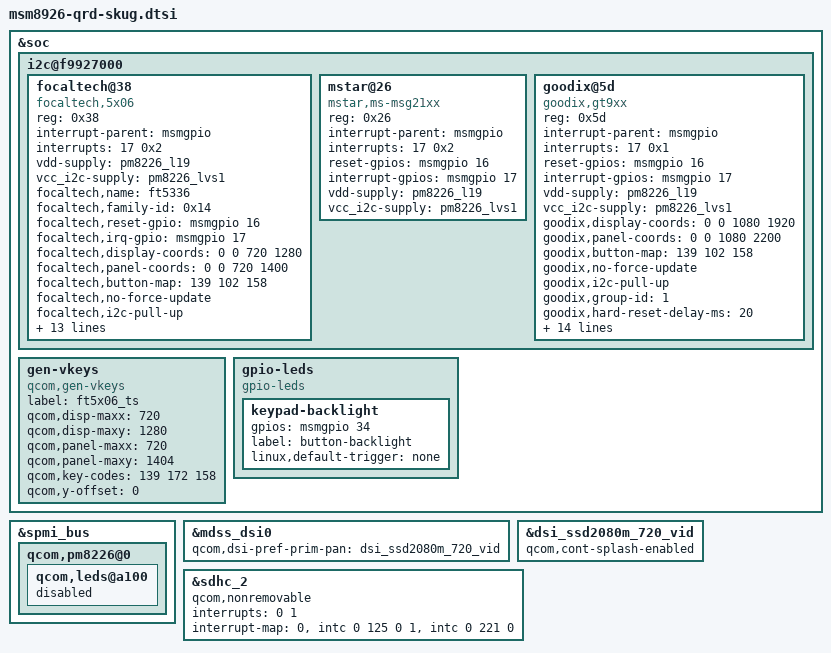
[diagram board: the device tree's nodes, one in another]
/* Copyright (c) 2013-2014, The Linux Foundation. All rights reserved.
 *
 * This program is free software; you can redistribute it and/or modify
 * it under the terms of the GNU General Public License version 2 and
 * only version 2 as published by the Free Software Foundation.
 *
 * This program is distributed in the hope that it will be useful,
 * but WITHOUT ANY WARRANTY; without even the implied warranty of
 * MERCHANTABILITY or FITNESS FOR A PARTICULAR PURPOSE.  See the
 * GNU General Public License for more details.
 */

/include/ "msm8226-qrd.dtsi"
/include/ "msm8926-camera-sensor-qrd.dtsi"

//xiangdong delete for battery identify issue begin
/*
&qrd_batterydata {
	qcom,rpull-up-kohm = <100>;
	qcom,vref-batt-therm = <1800000>;

	/include/ "batterydata-qrd-4v2-2000mah.dtsi"
};

&pm8226_bms {
	qcom,battery-data = <&qrd_batterydata>;
};

&pm8226_chg {
	qcom,battery-data = <&qrd_batterydata>;
};
*/
//xiangdong delete for battery identify issue end

&soc {
	i2c@f9927000 { /* BLSP1 QUP5 */
		focaltech@38 {
			compatible = "focaltech,5x06";
			reg = <0x38>;
			interrupt-parent = <&msmgpio>;
			interrupts = <17 0x2>;
			vdd-supply = <&pm8226_l19>;
			vcc_i2c-supply = <&pm8226_lvs1>;
			focaltech,name = "ft5336";
			focaltech,family-id = <0x14>;
			focaltech,reset-gpio = <&msmgpio 16 0x00>;
			focaltech,irq-gpio = <&msmgpio 17 0x00>;
			focaltech,display-coords = <0 0 720 1280>;
			focaltech,panel-coords = <0 0 720 1400>;
			focaltech,button-map= <139 102 158>;
			focaltech,no-force-update;
			focaltech,i2c-pull-up;
			focaltech,group-id = <1>;
			focaltech,hard-reset-delay-ms = <20>;
			focaltech,soft-reset-delay-ms = <200>;
			focaltech,num-max-touches = <5>;
			focaltech,fw-name = "ft_8926_qrd_fw.bin";
			focaltech,fw-delay-aa-ms = <30>;
			focaltech,fw-delay-55-ms = <30>;
			focaltech,fw-upgrade-id1 = <0x11>;
			focaltech,fw-upgrade-id2 = <0x11>;
			focaltech,fw-delay-readid-ms = <10>;
			focaltech,fw-delay-era-flsh-ms = <2000>;
			focaltech,fw-auto-cal;
			focaltech,ignore-id-check;
		};
		/* lichm merge for mstar tp begin */
		mstar@26 {
			compatible = "mstar,ms-msg21xx";
			reg = <0x26>;
			interrupt-parent = <&msmgpio>;
			interrupts = <17 0x2>;
			reset-gpios = <&msmgpio 16 0x00>;
			interrupt-gpios = <&msmgpio 17 0x00>;
			vdd-supply = <&pm8226_l19>;
			vcc_i2c-supply = <&pm8226_lvs1>;
		};
		/* lichm merge for mstar tp end */

		/* wuchx merge for goodix tp begin */
		goodix@5d {
			compatible = "goodix,gt9xx";
			reg = <0x5d>;
			interrupt-parent = <&msmgpio>;
			interrupts = <17 0x1>;
			reset-gpios = <&msmgpio 16 0x00>;
			interrupt-gpios = <&msmgpio 17 0x00>;
			vdd-supply = <&pm8226_l19>;
			vcc_i2c-supply = <&pm8226_lvs1>;
			/*TYDRV:liujie add for goodix TP dt begin 20140613*/
			goodix,display-coords = <0 0 1080 1920>;
			goodix,panel-coords = <0 0 1080 2200>;
			goodix,button-map= <139 102 158>;
			goodix,no-force-update;
			goodix,i2c-pull-up;
			goodix,group-id = <1>;
			goodix,hard-reset-delay-ms = <20>;
			goodix,soft-reset-delay-ms = <200>;
			goodix,num-max-touches = <5>;
			goodix,fw-name = "gtp_8926_qrd_fw.bin";
			goodix,fw-delay-aa-ms = <30>;
			goodix,fw-delay-55-ms = <30>;
			goodix,fw-upgrade-id1 = <0x11>;
			goodix,fw-upgrade-id2 = <0x11>;
			goodix,fw-delay-readid-ms = <10>;
			goodix,fw-delay-era-flsh-ms = <2000>;
			goodix,fw-auto-cal;
			goodix,ignore-id-check;
			goodix,cfg-count = <1 0 0 0 0 0 0>;
			goodix,cfg-data0 = [
			4A 38 04 80 07 05 
			0C 41 01 08 32 0F 
			50 32 03 03 00 00 
			00 00 00 00 00 17 
			19 1E 14 88 28 FF 
			25 27 82 0A D3 07 
			00 03 03 11 00 00 
			00 00 00 00 00 08 
			0A 00 00 1E 37 94 
			D5 02 08 00 00 04 
			9B 1F 00 8D 24 00 
			7F 28 00 75 2D 00 
			6C 33 00 6C 18 40 
			70 00 50 45 20 AA 
			AA 27 00 00 00 00 
			00 00 00 00 00 00 
			00 00 00 00 00 00 
			00 00 00 00 00 00 
			00 00 00 00 00 01 
			02 03 04 05 06 07 
			0E 0D 0C 0B 0A 09 
			08 15 14 13 12 11 
			10 0F 16 17 18 19 
			1A 1B 1C 1D 1E 1F 
			20 22 24 28 29 2A 
			0C 0A 08 06 05 04 
			02 00 FF 00 00 00 
			00 00 00 00 00 00 
			00 00 00 00 00 00 
			00 00 00 00 00 00 
			00 00 00 00 00 00 
			00 00 00 00 00 00 
			00 00 00 00 00 00 
			00 00 00 00 00 00 
			00 00 00 00 00 00 
			00 00 00 00 00 00 
			00 00 00 00 00 00 
			00 00 00 00 61 01];
			/*TYDRV:liujie add for goodix TP dt end 20140613*/
		};
		/* wuchx merge for goodix tp end */
	};

	gen-vkeys {
		compatible = "qcom,gen-vkeys";
		label = "ft5x06_ts";
		qcom,disp-maxx = <720>;
		qcom,disp-maxy = <1280>;
		qcom,panel-maxx = <720>;
		qcom,panel-maxy = <1404>;
		qcom,key-codes = <139 172 158>;
		qcom,y-offset = <0>;
	};

	gpio-leds {
		compatible = "gpio-leds";
		keypad-backlight {
			gpios = <&msmgpio 34 0>;
			label = "button-backlight";
			linux,default-trigger = "none";
		};
	};
};

&spmi_bus {
	qcom,pm8226@0 {
		qcom,leds@a100 {
			status = "disable";
			};
		};
};

&mdss_dsi0 {
	qcom,dsi-pref-prim-pan = <&dsi_ssd2080m_720_vid>;
};

&dsi_ssd2080m_720_vid {
	qcom,cont-splash-enabled;
};

&sdhc_2 {
	qcom,nonremovable;

	interrupts = <0 1>;
	interrupt-map = <0 &intc 0 125 0
			1 &intc 0 221 0>;
	interrupt-names = "hc_irq", "pwr_irq";
	/delete-property/ cd-gpios;
};
